AUTOSAR XML (schema 4-0-3)
standard types defined: uint8, Boolean, UInt16, UInt32, UInt8
package /AUTOSAR_Platform/DataConstrs
  range DC_Boolean: raw 0..1
  range DC_UInt16: raw 0..65535
  range DC_UInt8: raw 0..255
package /PATAC/Facility/DataTypes/Implementation
  compu method COMPU_Boolean: 0=FALSE, 1=TRUE
  unit NoUnit: factor-si-to-unit=1, offset-si-to-unit=0
package /PATAC/MSM/ComponentTypes
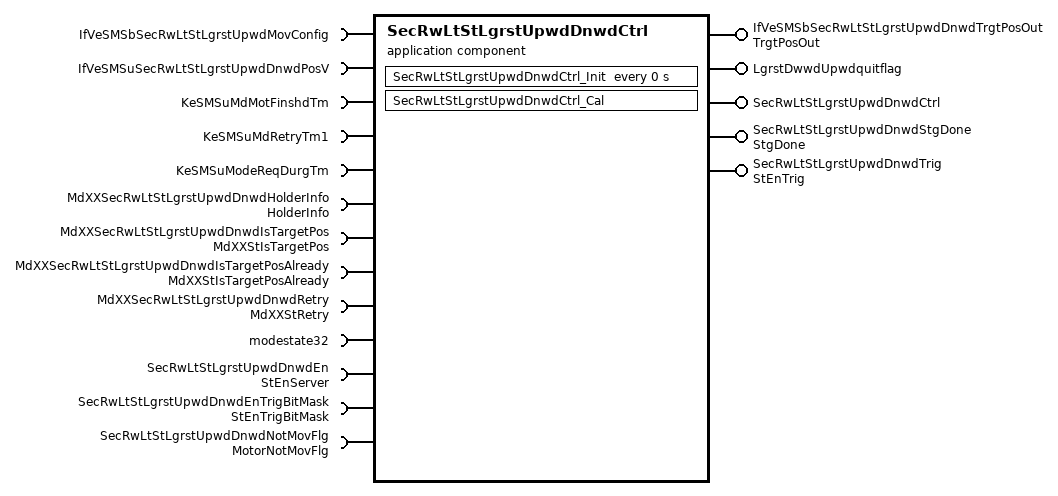
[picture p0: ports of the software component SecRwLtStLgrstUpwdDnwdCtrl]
  application sw component type SecRwLtStLgrstUpwdDnwdCtrl
    5 x provide port:
      IfVeSMSbSecRwLtStLgrstUpwdDnwdTrgtPosOut: nonqueued-sender-com-spec{data-element=TrgtPosOut/Val, init-value=0}, provided-interface=TrgtPosOut
      LgrstDwwdUpwdquitflag: nonqueued-sender-com-spec{data-element=LgrstDwwdUpwdquitflag/Val, init-value=0}, provided-interface=LgrstDwwdUpwdquitflag
      SecRwLtStLgrstUpwdDnwdCtrl: server-com-spec{operation=Cal, queue-length=1}, provided-interface=SecRwLtStLgrstUpwdDnwdCtrl
      SecRwLtStLgrstUpwdDnwdStgDone: nonqueued-sender-com-spec{data-element=StgDone/Val, init-value=0}, provided-interface=StgDone
      SecRwLtStLgrstUpwdDnwdTrig: nonqueued-sender-com-spec{data-element=StEnTrig/Val, init-value=0}, provided-interface=StEnTrig
    13 x require port:
      IfVeSMSbSecRwLtStLgrstUpwdMovConfig: nonqueued-receiver-com-spec{data-element=IfVeSMSbSecRwLtStLgrstUpwdMovConfig/Val, filter=data-filter-type=ALWAYS, init-value=0}, required-interface=IfVeSMSbSecRwLtStLgrstUpwdMovConfig
      IfVeSMSuSecRwLtStLgrstUpwdDnwdPosV: nonqueued-receiver-com-spec{data-element=IfVeSMSuSecRwLtStLgrstUpwdDnwdPosV/Val, filter=data-filter-type=ALWAYS, init-value=0}, required-interface=IfVeSMSuSecRwLtStLgrstUpwdDnwdPosV
      KeSMSuMdMotFinshdTm: parameter-require-com-spec{init-value=0, parameter=KeSMSuMdMotFinshdTm/Val}, required-interface=KeSMSuMdMotFinshdTm
      KeSMSuMdRetryTm1: parameter-require-com-spec{init-value=0, parameter=KeSMSuMdRetryTm1/Val}, required-interface=KeSMSuMdRetryTm1
      KeSMSuModeReqDurgTm: parameter-require-com-spec{init-value=0, parameter=KeSMSuModeReqDurgTm/Val}, required-interface=KeSMSuModeReqDurgTm
      MdXXSecRwLtStLgrstUpwdDnwdHolderInfo: nonqueued-receiver-com-spec{data-element=HolderInfo/Val, filter=data-filter-type=ALWAYS, init-value=0}, required-interface=HolderInfo
      MdXXSecRwLtStLgrstUpwdDnwdIsTargetPos: nonqueued-receiver-com-spec{data-element=MdXXStIsTargetPos/Val, filter=data-filter-type=ALWAYS, init-value=0}, required-interface=MdXXStIsTargetPos
      MdXXSecRwLtStLgrstUpwdDnwdIsTargetPosAlready: nonqueued-receiver-com-spec{data-element=MdXXStIsTargetPosAlready/Val, filter=data-filter-type=ALWAYS, init-value=0}, required-interface=MdXXStIsTargetPosAlready
      MdXXSecRwLtStLgrstUpwdDnwdRetry: nonqueued-receiver-com-spec{data-element=MdXXStRetry/Val, filter=data-filter-type=ALWAYS, init-value=0}, required-interface=MdXXStRetry
      modestate32: nonqueued-receiver-com-spec{data-element=modestate32/Val, filter=data-filter-type=ALWAYS, init-value=0}, required-interface=modestate32
      SecRwLtStLgrstUpwdDnwdEn: required-com-specs=[Clear, Get, Set], required-interface=StEnServer
      SecRwLtStLgrstUpwdDnwdEnTrigBitMask: nonqueued-receiver-com-spec{data-element=StEnTrigBitMask/Val, filter=data-filter-type=ALWAYS, init-value=0}, required-interface=StEnTrigBitMask
      SecRwLtStLgrstUpwdDnwdNotMovFlg: nonqueued-receiver-com-spec{data-element=MotorNotMovFlg/Val, filter=data-filter-type=ALWAYS, init-value=0}, required-interface=MotorNotMovFlg
    behavior SecRwLtStLgrstUpwdDnwdCtrl_InternalBehavior
      operation invoked event OIT_SecRwLtStLgrstUpwdDnwdCtrl_Cal_SecRwLtStLgrstUpwdDnwdCtrl_Cal: start-on-event=SecRwLtStLgrstUpwdDnwdCtrl_Cal, operation=SecRwLtStLgrstUpwdDnwdCtrl.Cal
      timing event SecRwLtStLgrstUpwdDnwdCtrl_InitEvent: start-on-event=SecRwLtStLgrstUpwdDnwdCtrl_Init, period=0
      runnable SecRwLtStLgrstUpwdDnwdCtrl_Cal
        data-receive-point-by-arguments:
          9 x access:
            REC_IfVeSMSbSecRwLtStLgrstUpwdMovConfig_Val: accessed-variable=IfVeSMSbSecRwLtStLgrstUpwdMovConfig.Val
            REC_IfVeSMSuSecRwLtStLgrstUpwdDnwdPosV_Val: accessed-variable=IfVeSMSuSecRwLtStLgrstUpwdDnwdPosV.Val
            REC_MdXXSecRwLtStLgrstUpwdDnwdHolderInfo_Val: accessed-variable=MdXXSecRwLtStLgrstUpwdDnwdHolderInfo.Val
            REC_MdXXSecRwLtStLgrstUpwdDnwdIsTargetPos_Val: accessed-variable=MdXXSecRwLtStLgrstUpwdDnwdIsTargetPos.Val
            REC_MdXXSecRwLtStLgrstUpwdDnwdIsTargetPosAlready_Val: accessed-variable=MdXXSecRwLtStLgrstUpwdDnwdIsTargetPosAlready.Val
            REC_MdXXSecRwLtStLgrstUpwdDnwdRetry_Val: accessed-variable=MdXXSecRwLtStLgrstUpwdDnwdRetry.Val
            REC_modestate32_Val: accessed-variable=modestate32.Val
            REC_SecRwLtStLgrstUpwdDnwdEnTrigBitMask_Val: accessed-variable=SecRwLtStLgrstUpwdDnwdEnTrigBitMask.Val
            REC_SecRwLtStLgrstUpwdDnwdNotMovFlg_Val: accessed-variable=SecRwLtStLgrstUpwdDnwdNotMovFlg.Val
        data-send-points:
          4 x access:
            SEND_IfVeSMSbSecRwLtStLgrstUpwdDnwdTrgtPosOut_Val: accessed-variable=IfVeSMSbSecRwLtStLgrstUpwdDnwdTrgtPosOut.Val
            SEND_LgrstDwwdUpwdquitflag_Val: accessed-variable=LgrstDwwdUpwdquitflag.Val
            SEND_SecRwLtStLgrstUpwdDnwdStgDone_Val: accessed-variable=SecRwLtStLgrstUpwdDnwdStgDone.Val
            SEND_SecRwLtStLgrstUpwdDnwdTrig_Val: accessed-variable=SecRwLtStLgrstUpwdDnwdTrig.Val
        parameter access PA_KeSMSuMdMotFinshdTm_Val: accessed-parameter=KeSMSuMdMotFinshdTm.Val
        parameter access PA_KeSMSuMdRetryTm1_Val: accessed-parameter=KeSMSuMdRetryTm1.Val
        parameter access PA_KeSMSuModeReqDurgTm_Val: accessed-parameter=KeSMSuModeReqDurgTm.Val
        sync call SC_SecRwLtStLgrstUpwdDnwdEn_Get: operation=SecRwLtStLgrstUpwdDnwdEn.Get, timeout=0
      runnable SecRwLtStLgrstUpwdDnwdCtrl_Init
        parameter access PA_KeSMSuMdMotFinshdTm_Val: accessed-parameter=KeSMSuMdMotFinshdTm.Val
        parameter access PA_KeSMSuMdRetryTm1_Val: accessed-parameter=KeSMSuMdRetryTm1.Val
        parameter access PA_KeSMSuModeReqDurgTm_Val: accessed-parameter=KeSMSuModeReqDurgTm.Val
  swc implementation SecRwLtStLgrstUpwdDnwdCtrl_Implementation: behavior=SecRwLtStLgrstUpwdDnwdCtrl_InternalBehavior
    code-descriptors:
      code Default: artifact-descriptors=autosar-engineering-object={short-label=Default, category=SWSRC}
package /PATAC/MSM/ModeAdjust/CalPortInterface
  parameter interface KeSMSuMdMotFinshdTm
    parameter data prototype Val: sw-calibration-access=READ-WRITE, type=UInt16
  parameter interface KeSMSuModeReqDurgTm
    parameter data prototype Val: sw-calibration-access=READ-WRITE, type=UInt16
package /PATAC/MSM/ModeAdjust/Interfaces
  sender receiver interface IfVeSMSuSecRwLtStLgrstUpwdDnwdPosV: invalidation-policy{data-element=IfVeSMSuSecRwLtStLgrstUpwdDnwdPosV/Val, handle-invalid=DONT-INVALIDATE}
    data Val: type=Boolean
package /PATAC/MSM/ModeAdjust/PortInterface
  client server interface SecRwLtStLgrstUpwdDnwdCtrl
    operation Cal
  client server interface StEnServer
    operation Clear
      arg data: type=UInt8, direction=IN, server-argument-impl-policy=USE-ARGUMENT-TYPE
    operation Get
      arg data: type=UInt32, direction=OUT, server-argument-impl-policy=USE-ARGUMENT-TYPE
    operation Set
      arg data: type=UInt8, direction=IN, server-argument-impl-policy=USE-ARGUMENT-TYPE
  11 x sender receiver interface:
    HolderInfo: invalidation-policy{data-element=HolderInfo/Val, handle-invalid=DONT-INVALIDATE}
      data Val: type=UInt32
    LgrstDwwdUpwdquitflag: invalidation-policy{data-element=LgrstDwwdUpwdquitflag/Val, handle-invalid=DONT-INVALIDATE}
      data Val: type=Boolean
    MdXXStIsTargetPos: invalidation-policy{data-element=MdXXStIsTargetPos/Val, handle-invalid=DONT-INVALIDATE}
      data Val: type=UInt32
    MdXXStIsTargetPosAlready: invalidation-policy{data-element=MdXXStIsTargetPosAlready/Val, handle-invalid=DONT-INVALIDATE}
      data Val: type=UInt32
    MdXXStRetry: invalidation-policy{data-element=MdXXStRetry/Val, handle-invalid=DONT-INVALIDATE}
      data Val: type=UInt32
    modestate32: invalidation-policy{data-element=modestate32/Val, handle-invalid=DONT-INVALIDATE}
      data Val: type=UInt32
    MotorNotMovFlg: invalidation-policy{data-element=MotorNotMovFlg/Val, handle-invalid=DONT-INVALIDATE}
      data Val: type=Boolean
    StEnTrig: invalidation-policy{data-element=StEnTrig/Val, handle-invalid=DONT-INVALIDATE}
      data Val: type=Boolean
    StEnTrigBitMask: invalidation-policy{data-element=StEnTrigBitMask/Val, handle-invalid=DONT-INVALIDATE}
      data Val: type=UInt32
    StgDone: invalidation-policy{data-element=StgDone/Val, handle-invalid=DONT-INVALIDATE}
      data Val: type=Boolean
    TrgtPosOut: invalidation-policy{data-element=TrgtPosOut/Val, handle-invalid=DONT-INVALIDATE}
      data Val: type=Boolean
package /PATAC/MSM/PortInterfaces
  parameter interface KeSMSuMdRetryTm1
    parameter data prototype Val: sw-calibration-access=READ-WRITE, type=UInt8
  sender receiver interface IfVeSMSbSecRwLtStLgrstUpwdMovConfig: invalidation-policy{data-element=IfVeSMSbSecRwLtStLgrstUpwdMovConfig/Val, handle-invalid=DONT-INVALIDATE}
    data Val: type=Boolean
